# STM32G554xx register map
File version: 1.0
Registers are 32-bit, read-write, reset 0x0 unless marked. A register's access mark holds for its fields unless they carry their own. Offsets are from the block's base; [hi:lo] are bit positions; {n}, {i} and the like mark numbered series.

## PLAY1 — Programmable Logic Array (PLAY)
Base 0x40011400
0x00 CFGCR — PLAY configuration control register
  [0] UNLOCK — Unlock configuration
0x04 SECCFGR — PLAY security attributes configuration register
  [1:0] SEC — Secure access control
0x08 PRIVCFGR — PLAY privilege attributes configuration register
  [1:0] PRIV — Privilege access control
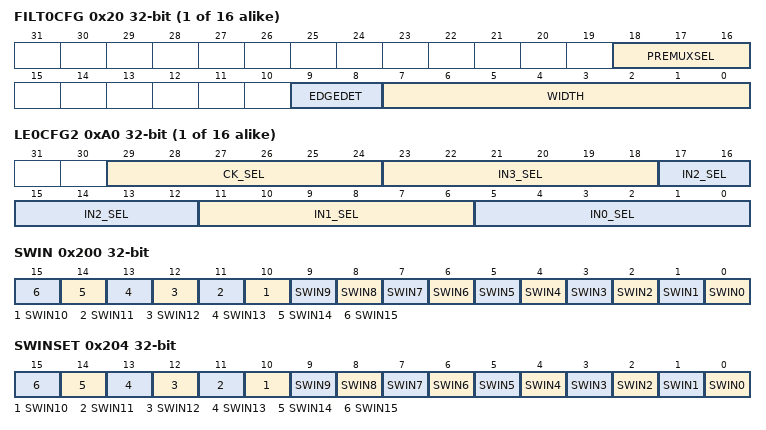
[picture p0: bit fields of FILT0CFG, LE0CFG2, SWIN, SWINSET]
{0x20+4i} FILT{i}CFG (i=0..15) — PLAY filter 0 configuration register
  [18:16] PREMUXSEL — Input pre-multiplexer select
  [9:8] EDGEDET — Edge detection mode
  [7:0] WIDTH — Minimum pulse width
{0x60+4i} LE{i}CFG1 (i=0..15) — PLAY logic element 0 configuration register 1
  [15:0] LUT — Look-up table contents
{0xA0+4i} LE{i}CFG2 (i=0..15) — PLAY logic element 0 configuration register 2
  [29:24] CK_SEL — Clock enable selection
  [6n+5:6n] IN{n}_SEL (n=0..3) — Logic element input {n} selection
{0x100+4i} OUT{i}CFG (i=0..15) — PLAY output 0 configuration register
  [4:0] SEL — Output source selection
0x200 SWIN — PLAY software input status register
  [n] SWIN{n} (n=0..15) — Input swiny state
0x204 SWINSET — PLAY software input set register
  [n] SWIN{n} (n=0..15) — Set PLAY_SWIN.SWINy
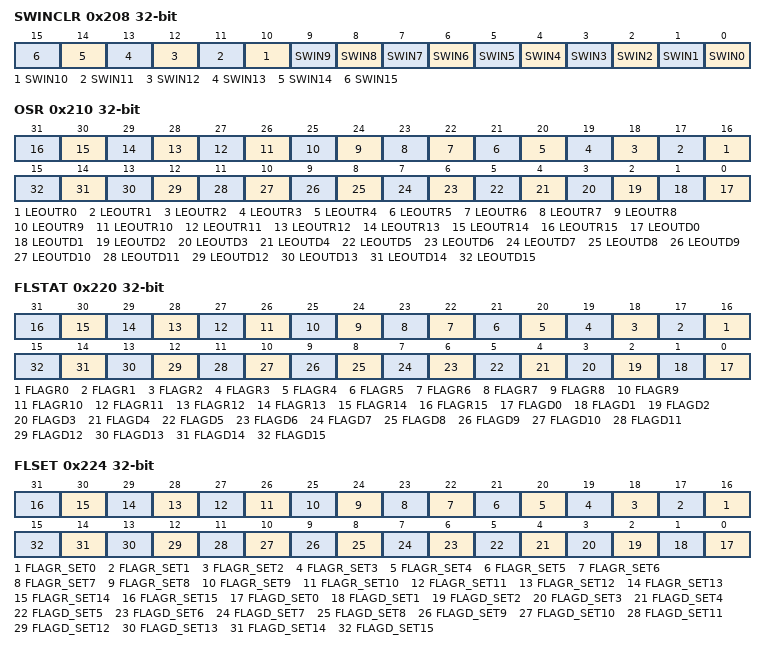
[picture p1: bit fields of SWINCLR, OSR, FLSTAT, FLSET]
0x208 SWINCLR — PLAY software input clear register
  [n] SWIN{n} (n=0..15) — Reset PLAY_SWIN.SWINy
0x210 OSR ro — PLAY output status register
  [n+16] LEOUTR{n} (n=0..15)
  [n] LEOUTD{n} (n=0..15) — State of LE direct outputs leoutdy
0x220 FLSTAT ro — PLAY flag status register
  [n+16] FLAGR{n} (n=0..15)
  [n] FLAGD{n} (n=0..15) — Flag state for LEy direct output
0x224 FLSET — PLAY flag set register
  [n+16] FLAGR_SET{n} (n=0..15) — Flag set for LEy registered output
  [n] FLAGD_SET{n} (n=0..15) — Flag set for LEy direct output
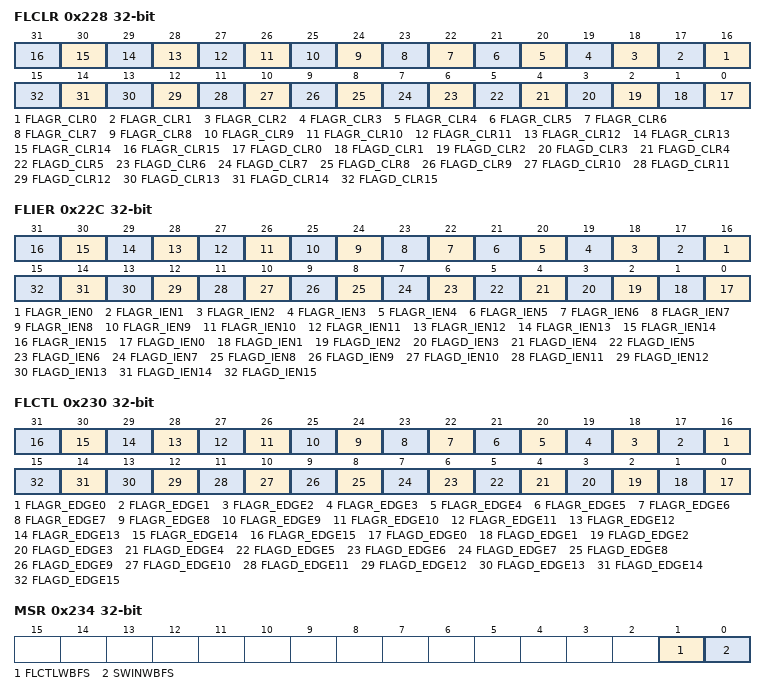
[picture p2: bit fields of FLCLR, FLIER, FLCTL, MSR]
0x228 FLCLR — PLAY flag clear register
  [n+16] FLAGR_CLR{n} (n=0..15)
  [n] FLAGD_CLR{n} (n=0..15) — Flag clear for LEy direct output
0x22C FLIER — PLAY flag interrupt enable register
  [n+16] FLAGR_IEN{n} (n=0..15), [n] FLAGD_IEN{n} (n=0..15)
0x230 FLCTL — PLAY flag control register
  [n+16] FLAGR_EDGE{n} (n=0..15), [n] FLAGD_EDGE{n} (n=0..15)
0x234 MSR ro — PLAY miscellaneous status register
  [1] FLCTLWBFS, [0] SWINWBFS
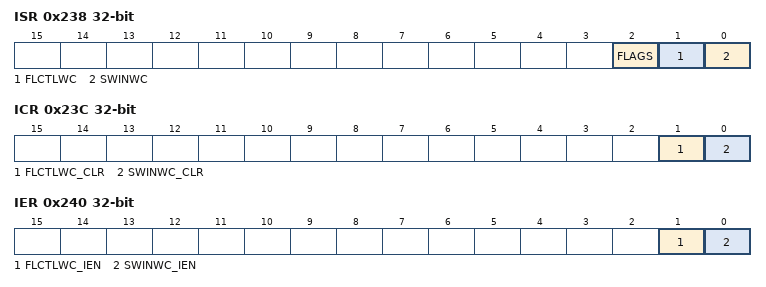
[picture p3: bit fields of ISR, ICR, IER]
0x238 ISR ro — PLAY interrupt status register
  [2] FLAGS — Flag interrupts status
  [1] FLCTLWC
  [0] SWINWC
0x23C ICR — PLAY interrupt clear register
  [1] FLCTLWC_CLR, [0] SWINWC_CLR
0x240 IER — PLAY interrupt enable register
  [1] FLCTLWC_IEN, [0] SWINWC_IEN

## USB_DRD_FS — Universal serial bus full-speed host/device interface (USB)
Base 0x40016000
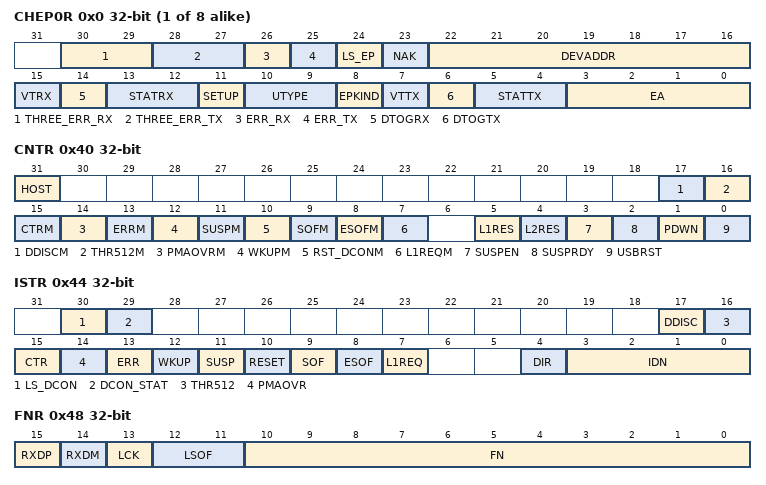
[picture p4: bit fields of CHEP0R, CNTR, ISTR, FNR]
{0x0+4i} CHEP{i}R (i=0..7) — USB endpoint/channel {i} register
  [30:29] THREE_ERR_RX — Three errors for an IN transaction
  [28:27] THREE_ERR_TX
  [26] ERR_RX
  [25] ERR_TX
  [24] LS_EP
  [23] NAK — Host mode
  [22:16] DEVADDR — Host mode
  [15] VTRX — USB valid transaction received
  [14] DTOGRX
  [13:12] STATRX
  [11] SETUP — Setup transaction completed
  [10:9] UTYPE — USB type of transaction
  [8] EPKIND — endpoint/channel kind
  [7] VTTX — Valid USB transaction transmitted
  [6] DTOGTX
  [5:4] STATTX
  [3:0] EA — endpoint/channel address
0x40 CNTR — USB control register
  [31] HOST — HOST mode
  [17] DDISCM — Device disconnection mask
  [16] THR512M — 512 byte threshold interrupt mask
  [15] CTRM — Correct transfer interrupt mask
  [14] PMAOVRM
  [13] ERRM — Error interrupt mask
  [12] WKUPM — Wake-up interrupt mask
  [11] SUSPM — Suspend mode interrupt mask
  [10] RST_DCONM
  [9] SOFM — Start of frame interrupt mask
  [8] ESOFM
  [7] L1REQM — LPM L1 state request interrupt mask
  [5] L1RES — L1 remote wake-up / resume driver
  [4] L2RES — L2 remote wake-up / resume driver
  [3] SUSPEN — Suspend state enable
  [2] SUSPRDY — Suspend state effective
  [1] PDWN — Power down
  [0] USBRST — USB Reset
0x44 ISTR — USB interrupt status register
  [30] LS_DCON — Low speed device connected
  [29] DCON_STAT — Device connection status
  [17] DDISC — Device connection
  [16] THR512 — 512 byte threshold interrupt
  [15] CTR — Completed transfer in host mode
  [14] PMAOVR — Packet memory area over / underrun
  [13] ERR — Error
  [12] WKUP — Wake-up
  [11] SUSP — Suspend mode request
  [10] RESET — RESET Mask
  [9] SOF — Start of frame
  [8] ESOF — Expected start of frame
  [7] L1REQ — LPM L1 state request
  [4] DIR — Direction of transaction
  [3:0] IDN
0x48 FNR ro — USB frame number register
  [15] RXDP — Receive data + line status
  [14] RXDM — Receive data - line status
  [13] LCK — Locked
  [12:11] LSOF — Lost SOF
  [10:0] FN — Frame number
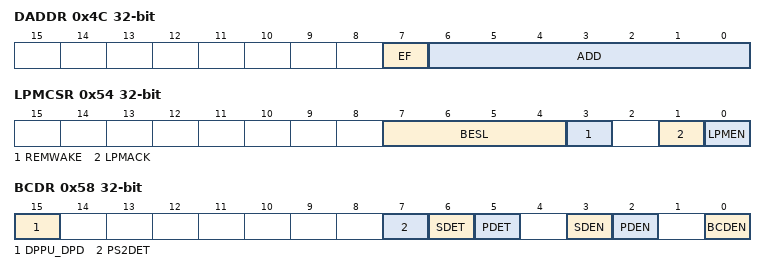
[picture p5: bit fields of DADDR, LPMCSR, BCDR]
0x4C DADDR — USB Device address
  [7] EF — Enable function
  [6:0] ADD — Device address
0x54 LPMCSR — USB LPM control and status register
  [7:4] BESL — BESL value
  [3] REMWAKE — bRemoteWake value
  [1] LPMACK — LPM token acknowledge enable
  [0] LPMEN — LPM support enable
0x58 BCDR — USB battery charging detector
  [15] DPPU_DPD — DP pull-up / DPDM pull-down
  [7] PS2DET — DM pull-up detection status
  [6] SDET — Secondary detection (SD) status
  [5] PDET — Primary detection (PD) status
  [3] SDEN
  [2] PDEN — Primary detection (PD) mode enable
  [0] BCDEN
